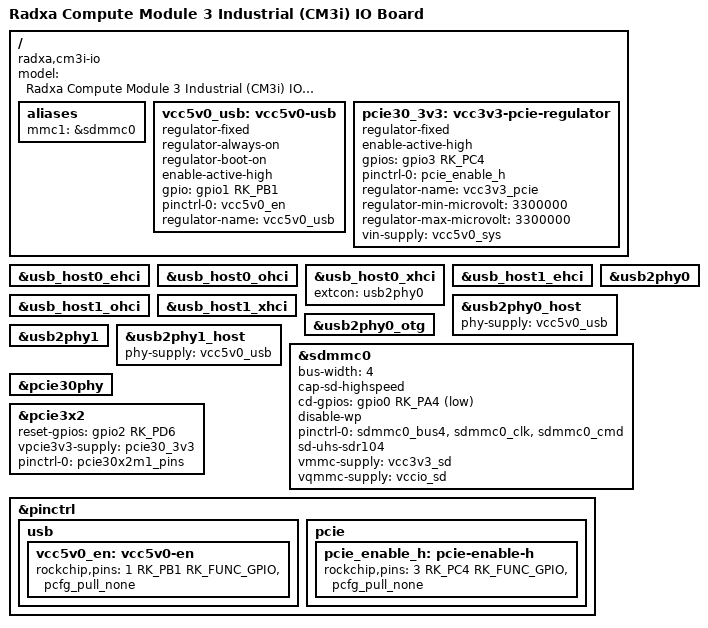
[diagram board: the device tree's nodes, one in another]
// SPDX-License-Identifier: (GPL-2.0+ OR MIT)

/dts-v1/;
#include "rk3568-radxa-cm3i.dtsi"

/ {
	model = "Radxa Compute Module 3 Industrial (CM3i) IO Board";
	compatible = "radxa,cm3i-io", "radxa,cm3i", "rockchip,rk3568";

	aliases {
		mmc1 = &sdmmc0;
	};

	vcc5v0_usb: vcc5v0-usb {
		compatible = "regulator-fixed";
		regulator-always-on;
		regulator-boot-on;
		enable-active-high;
		gpio = <&gpio1 RK_PB1 GPIO_ACTIVE_HIGH>;
		pinctrl-names = "default";
		pinctrl-0 = <&vcc5v0_en>;
		regulator-name = "vcc5v0_usb";
	};

	pcie30_3v3: vcc3v3-pcie-regulator {
		compatible = "regulator-fixed";
		enable-active-high;
		gpios = <&gpio3 RK_PC4 GPIO_ACTIVE_HIGH>;
		pinctrl-names = "pcie30_3v3";
		pinctrl-0 = <&pcie_enable_h>;
		regulator-name = "vcc3v3_pcie";
		regulator-min-microvolt = <3300000>;
		regulator-max-microvolt = <3300000>;
		vin-supply = <&vcc5v0_sys>;
	};
};

&usb_host0_ehci {
	status = "okay";
};

&usb_host0_ohci {
	status = "okay";
};

&usb_host0_xhci {
	extcon = <&usb2phy0>;
	status = "okay";
};

&usb_host1_ehci {
	status = "okay";
};

&usb_host1_ohci {
	status = "okay";
};

&usb_host1_xhci {
	status = "okay";
};

&usb2phy0 {
	status = "okay";
};

&usb2phy0_host {
	phy-supply = <&vcc5v0_usb>;
	status = "okay";
};

&usb2phy0_otg {
	status = "okay";
};

&usb2phy1 {
	status = "okay";
};

&usb2phy1_host {
	phy-supply = <&vcc5v0_usb>;
	status = "okay";
};

&sdmmc0 {
	bus-width = <4>;
	cap-sd-highspeed;
	cd-gpios = <&gpio0 RK_PA4 GPIO_ACTIVE_LOW>;
	disable-wp;
	pinctrl-names = "default";
	pinctrl-0 = <&sdmmc0_bus4 &sdmmc0_clk &sdmmc0_cmd>;
	sd-uhs-sdr104;
	vmmc-supply = <&vcc3v3_sd>;
	vqmmc-supply = <&vccio_sd>;
	status = "okay";
};

&pcie30phy {
	status = "okay";
};

&pcie3x2 {
	pinctrl-names = "default";
	reset-gpios = <&gpio2 RK_PD6 GPIO_ACTIVE_HIGH>;
	vpcie3v3-supply = <&pcie30_3v3>;
	pinctrl-0 = <&pcie30x2m1_pins>;
	status = "okay";
};

&pinctrl {
	usb {
		vcc5v0_en: vcc5v0-en {
			rockchip,pins = <1 RK_PB1 RK_FUNC_GPIO &pcfg_pull_none>;
		};
	};

	pcie {
		pcie_enable_h: pcie-enable-h {
			rockchip,pins = <3 RK_PC4 RK_FUNC_GPIO &pcfg_pull_none>;
		};
	};
};
